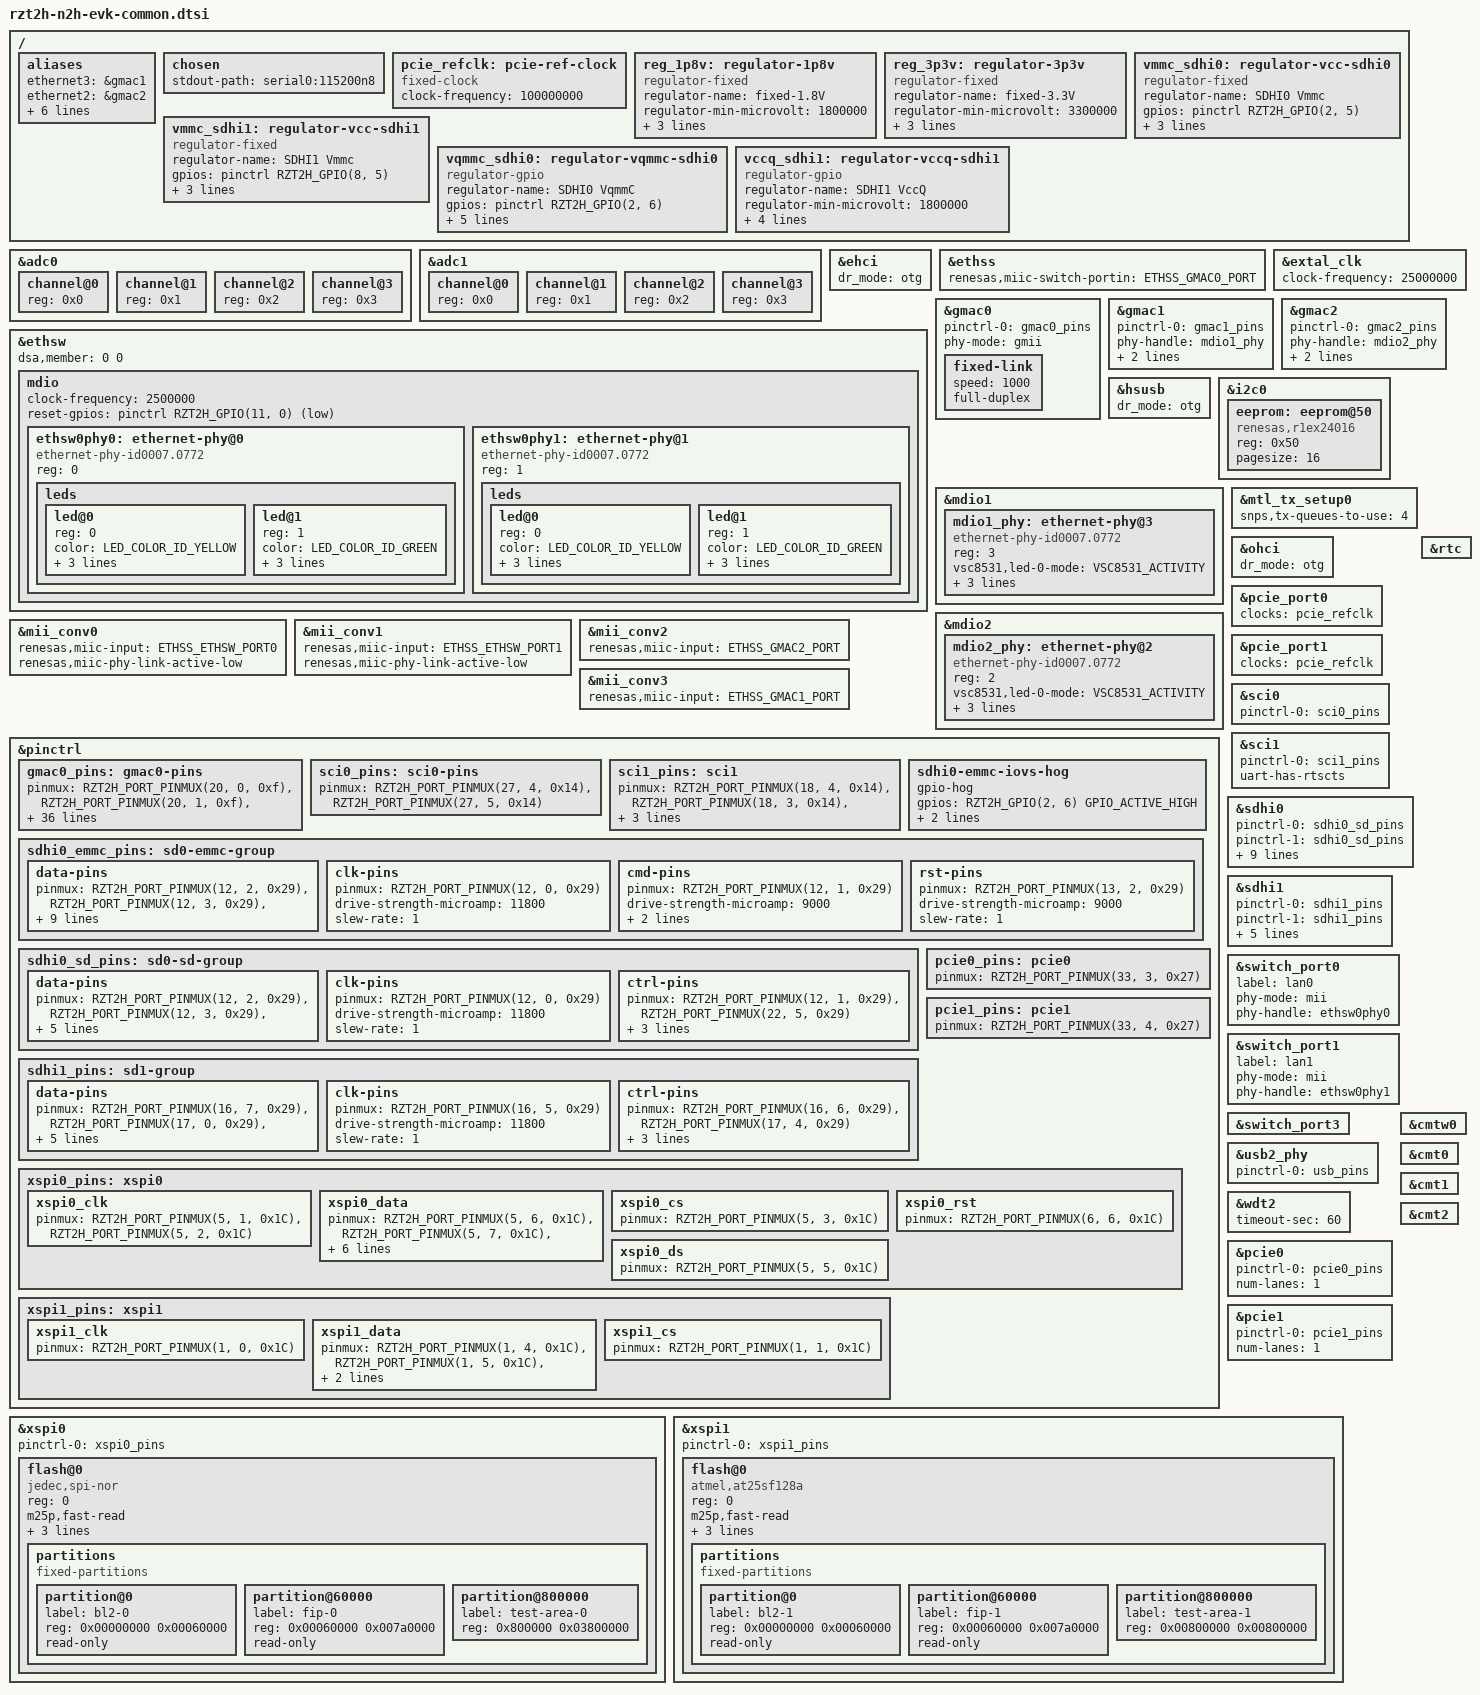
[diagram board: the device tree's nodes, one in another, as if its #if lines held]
// SPDX-License-Identifier: (GPL-2.0-only OR BSD-2-Clause)
/*
 * Common Device Tree Source for the RZ/T2H and RZ/N2H EVK boards.
 *
 * Copyright (C) 2025 Renesas Electronics Corp.
 */

#include <dt-bindings/gpio/gpio.h>
#include <dt-bindings/leds/common.h>
#include <dt-bindings/net/mscc-phy-vsc8531.h>
#include <dt-bindings/net/renesas,r9a09g077-pcs-miic.h>
#include <dt-bindings/pinctrl/renesas,r9a09g077-pinctrl.h>

/ {
	aliases {
		ethernet3 = &gmac1;
		ethernet2 = &gmac2;
		i2c0 = &i2c0;
		i2c1 = &i2c1;
		mmc0 = &sdhi0;
		mmc1 = &sdhi1;
		serial0 = &sci0;
		serial1 = &sci1;
	};

	chosen {
		stdout-path = "serial0:115200n8";
	};

	pcie_refclk: pcie-ref-clock {
		compatible = "fixed-clock";
		#clock-cells = <0>;
		clock-frequency = <100000000>;
	};

	reg_1p8v: regulator-1p8v {
		compatible = "regulator-fixed";
		regulator-name = "fixed-1.8V";
		regulator-min-microvolt = <1800000>;
		regulator-max-microvolt = <1800000>;
		regulator-boot-on;
		regulator-always-on;
	};

	reg_3p3v: regulator-3p3v {
		compatible = "regulator-fixed";
		regulator-name = "fixed-3.3V";
		regulator-min-microvolt = <3300000>;
		regulator-max-microvolt = <3300000>;
		regulator-boot-on;
		regulator-always-on;
	};

	vmmc_sdhi0: regulator-vcc-sdhi0 {
		compatible = "regulator-fixed";
		regulator-name = "SDHI0 Vmmc";
#if SD0_SD
		gpios = <&pinctrl RZT2H_GPIO(2, 5) GPIO_ACTIVE_HIGH>;
		enable-active-high;
#endif
		regulator-min-microvolt = <3300000>;
		regulator-max-microvolt = <3300000>;
	};

	vmmc_sdhi1: regulator-vcc-sdhi1 {
		compatible = "regulator-fixed";
		regulator-name = "SDHI1 Vmmc";
		gpios = <&pinctrl RZT2H_GPIO(8, 5) GPIO_ACTIVE_HIGH>;
		enable-active-high;
		regulator-min-microvolt = <3300000>;
		regulator-max-microvolt = <3300000>;
	};

#if SD0_SD
	vqmmc_sdhi0: regulator-vqmmc-sdhi0 {
		compatible = "regulator-gpio";
		regulator-name = "SDHI0 VqmmC";
		gpios = <&pinctrl RZT2H_GPIO(2, 6) GPIO_ACTIVE_HIGH>;
		regulator-min-microvolt = <1800000>;
		regulator-max-microvolt = <3300000>;
		gpios-states = <0>;
		states = <3300000 0>, <1800000 1>;
		regulator-ramp-delay = <60>;
	};
#endif

#if SD1_MICRO_SD
	vccq_sdhi1: regulator-vccq-sdhi1 {
		compatible = "regulator-gpio";
		regulator-name = "SDHI1 VccQ";
		regulator-min-microvolt = <1800000>;
		regulator-max-microvolt = <3300000>;
		gpios = <&pinctrl RZT2H_GPIO(8, 6) GPIO_ACTIVE_HIGH>;
		gpios-states = <0>;
		states = <3300000 0>, <1800000 1>;
	};
#endif
};

/*
 * ADC0 AN000 can be connected to a potentiometer on the board or
 * exposed on ADC header.
 *
 * T2H:
 * SW17[1] = ON, SW17[2] = OFF - Potentiometer
 * SW17[1] = OFF, SW17[2] = ON  - CN41 header
 * N2H:
 * DSW6[1] = OFF, DSW6[2] = ON - Potentiometer
 * DSW6[1] = ON, DSW6[2] = OFF - CN3 header
 */
&adc0 {
	status = "okay";

	channel@0 {
		reg = <0x0>;
	};

	channel@1 {
		reg = <0x1>;
	};

	channel@2 {
		reg = <0x2>;
	};

	channel@3 {
		reg = <0x3>;
	};
};

/*
 * ADC1 AN100 can be exposed on ADC header or on mikroBUS connector.
 *
 * T2H:
 * SW18[1] = ON, SW18[2] = OFF - CN42 header
 * SW18[1] = OFF, SW18[2] = ON - mikroBUS
 * N2H:
 * DSW6[3] = ON, DSW6[4] = OFF - CN4 header
 * DSW6[3] = OFF, DSW6[4] = ON - mikroBUS
 *
 * ADC1 AN101 can be exposed on ADC header or on Grove2 connector.
 *
 * T2H:
 * SW18[3] = ON, SW18[4] = OFF - CN42 header
 * SW18[3] = OFF, SW18[4] = ON - Grove2
 * N2H:
 * DSW6[5] = ON, DSW6[6] = OFF - CN4 header
 * DSW6[5] = OFF, DSW6[6] = ON - Grove2
 *
 * ADC1 AN102 can be exposed on ADC header or on Grove2 connector.
 *
 * T2H:
 * SW18[5] = ON, SW18[6] = OFF - CN42 header
 * SW18[5] = OFF, SW18[6] = ON - Grove2
 * N2H:
 * DSW6[7] = ON, DSW6[8] = OFF - CN4 header
 * DSW6[7] = OFF, DSW6[8] = ON - Grove2
 */
&adc1 {
	status = "okay";

	channel@0 {
		reg = <0x0>;
	};

	channel@1 {
		reg = <0x1>;
	};

	channel@2 {
		reg = <0x2>;
	};

	channel@3 {
		reg = <0x3>;
	};
};

&ehci {
	dr_mode = "otg";
	status = "okay";
};

&ethss {
	status = "okay";

	renesas,miic-switch-portin = <ETHSS_GMAC0_PORT>;
};

&ethsw {
	status = "okay";
	dsa,member = <0 0>;

	mdio {
		clock-frequency = <2500000>;
		#address-cells = <1>;
		#size-cells = <0>;
		/*
		 * P11_0 is connected to both the PHY0 and PHY1 reset pins.
		 *
		 * RZ/T2H EVK:
		 * SW6[2]: OFF, SW6[3]: ON, SW6[4]: OFF, SW6[5]: ON
		 *
		 * RZ/N2H EVK:
		 * DS12[3]: OFF, DS12[4]: ON
		 */
		reset-gpios = <&pinctrl RZT2H_GPIO(11, 0) GPIO_ACTIVE_LOW>;

		ethsw0phy0: ethernet-phy@0 {
			compatible = "ethernet-phy-id0007.0772", "ethernet-phy-ieee802.3-c22";
			reg = <0>;
			leds {
				#address-cells = <1>;
				#size-cells = <0>;

				led@0 {
					reg = <0>;
					color = <LED_COLOR_ID_YELLOW>;
					function = LED_FUNCTION_LAN;
					function-enumerator = <0>;
					default-state = "keep";
				};

				led@1 {
					reg = <1>;
					color = <LED_COLOR_ID_GREEN>;
					function = LED_FUNCTION_LAN;
					function-enumerator = <1>;
					default-state = "keep";
				};
			};
		};

		ethsw0phy1: ethernet-phy@1 {
			compatible = "ethernet-phy-id0007.0772", "ethernet-phy-ieee802.3-c22";
			reg = <1>;
			leds {
				#address-cells = <1>;
				#size-cells = <0>;

				led@0 {
					reg = <0>;
					color = <LED_COLOR_ID_YELLOW>;
					function = LED_FUNCTION_LAN;
					function-enumerator = <0>;
					default-state = "keep";
				};

				led@1 {
					reg = <1>;
					color = <LED_COLOR_ID_GREEN>;
					function = LED_FUNCTION_LAN;
					function-enumerator = <1>;
					default-state = "keep";
				};
			};
		};
	};
};

&extal_clk {
	clock-frequency = <25000000>;
};

&gmac0 {
	pinctrl-0 = <&gmac0_pins>;
	pinctrl-names = "default";
	status = "okay";
	phy-mode = "gmii";

	fixed-link {
		speed = <1000>;
		full-duplex;
	};
};

#if (SEL_GMAC1_OTHERS)
&gmac1 {
	pinctrl-0 = <&gmac1_pins>;
	pinctrl-names = "default";
	phy-handle = <&mdio1_phy>;
	phy-mode = "rgmii-id";
	pcs-handle = <&mii_conv3>;
	status = "okay";
};
#endif

&gmac2 {
	pinctrl-0 = <&gmac2_pins>;
	pinctrl-names = "default";
	phy-handle = <&mdio2_phy>;
	phy-mode = "rgmii-id";
	pcs-handle = <&mii_conv2>;
	status = "okay";
};

&hsusb {
	dr_mode = "otg";
	status = "okay";
};

&i2c0 {
	eeprom: eeprom@50 {
		compatible = "renesas,r1ex24016", "atmel,24c16";
		reg = <0x50>;
		pagesize = <16>;
	};
};

&mdio1 {
	mdio1_phy: ethernet-phy@3 {
		compatible = "ethernet-phy-id0007.0772", "ethernet-phy-ieee802.3-c22";
		reg = <3>;
		vsc8531,led-0-mode = <VSC8531_ACTIVITY>;
		vsc8531,led-1-mode = <VSC8531_LINK_ACTIVITY>;
		reset-assert-us = <2000>;
		reset-deassert-us = <15000>;
	};
};

&mdio2 {
	mdio2_phy: ethernet-phy@2 {
		compatible = "ethernet-phy-id0007.0772", "ethernet-phy-ieee802.3-c22";
		reg = <2>;
		vsc8531,led-0-mode = <VSC8531_ACTIVITY>;
		vsc8531,led-1-mode = <VSC8531_LINK_ACTIVITY>;
		reset-assert-us = <2000>;
		reset-deassert-us = <15000>;
	};
};

&mii_conv0 {
	renesas,miic-input = <ETHSS_ETHSW_PORT0>;
	renesas,miic-phy-link-active-low;
	status = "okay";
};

&mii_conv1 {
	renesas,miic-input = <ETHSS_ETHSW_PORT1>;
	renesas,miic-phy-link-active-low;
	status = "okay";
};

&mii_conv2 {
	renesas,miic-input = <ETHSS_GMAC2_PORT>;
	status = "okay";
};

&mii_conv3 {
	renesas,miic-input = <ETHSS_GMAC1_PORT>;
	status = "okay";
};

/*
 * The Tx fifo depth is 8192 and we have 8 Tx queues available, so in
 * total we have 1024 bytes per queue. When using as a CPU port in a DSA
 * configuration, MTU is configured to 1500 bytes which is larger than the
 * per-queue fifo size. Reduce the number of Tx queues to 4 to have
 * 2048 bytes per queue to accommodate the MTU.
 */
&mtl_tx_setup0 {
	snps,tx-queues-to-use = <4>;
};

&ohci {
	dr_mode = "otg";
	status = "okay";
};

&pcie_port0 {
	clocks = <&pcie_refclk>;
	clock-names = "ref";
};

&pcie_port1 {
	clocks = <&pcie_refclk>;
	clock-names = "ref";
};

&pinctrl {
	/*
	 * GMAC0 Pin Configuration:
	 * ------------------------
	 *
	 * RZ/T2H EVK:
	 * Signal     | Pin     | SW4 Settings
	 * -----------|---------|-------------------------
	 * ETH1_CRS   | P27_0   | SW4[1]: ON, SW4[2]: OFF
	 * ETH1_COL   | P27_1   | SW4[3]: ON, SW4[4]: OFF
	 *
	 * RZ/N2H EVK:
	 * Signal     | Pin     | DSW13 and DSW21 Settings
	 * -----------|---------|-------------------------
	 * ETH1_TXER  | P26_6   | DSW21[1]: ON, DSW21[2]: OFF, DSW21[3]: ON
	 * ETH1_RXER  | P26_7   | DSW13[1]: ON, DSW13[2]: OFF
	 * ETH1_CRS   | P27_0   | DSW13[3]: ON, DSW13[4]: OFF
	 * ETH1_COL   | P27_1   | DSW13[5]: ON, DSW13[6]: OFF
	 */
	gmac0_pins: gmac0-pins {
		pinmux = <RZT2H_PORT_PINMUX(20, 0, 0xf)>, /* ETH0_TXCLK */
			 <RZT2H_PORT_PINMUX(20, 1, 0xf)>, /* ETH0_TXD0 */
			 <RZT2H_PORT_PINMUX(20, 2, 0xf)>, /* ETH0_TXD1 */
			 <RZT2H_PORT_PINMUX(20, 3, 0xf)>, /* ETH0_TXD2 */
			 <RZT2H_PORT_PINMUX(20, 4, 0xf)>, /* ETH0_TXD3 */
			 <RZT2H_PORT_PINMUX(20, 5, 0xf)>, /* ETH0_TXEN */
			 <RZT2H_PORT_PINMUX(20, 6, 0xf)>, /* ETH0_RXCLK */
			 <RZT2H_PORT_PINMUX(20, 7, 0xf)>, /* ETH0_RXD0 */
			 <RZT2H_PORT_PINMUX(21, 0, 0xf)>, /* ETH0_RXD1 */
			 <RZT2H_PORT_PINMUX(21, 1, 0xf)>, /* ETH0_RXD2 */
			 <RZT2H_PORT_PINMUX(21, 2, 0xf)>, /* ETH0_RXD3 */
			 <RZT2H_PORT_PINMUX(21, 3, 0xf)>, /* ETH0_RXDV */
			 <RZT2H_PORT_PINMUX(22, 1, 0xf)>, /* ETH0_TXER */
			 <RZT2H_PORT_PINMUX(22, 2, 0xf)>, /* ETH0_RXER */
			 <RZT2H_PORT_PINMUX(22, 3, 0xf)>, /* ETH0_CRS */
			 <RZT2H_PORT_PINMUX(22, 4, 0xf)>, /* ETH0_COL */
			 <RZT2H_PORT_PINMUX(21, 7, 0x2)>, /* ETH0_REFCLK */
			 <RZT2H_PORT_PINMUX(24, 5, 0xf)>, /* ETH1_TXCLK */
			 <RZT2H_PORT_PINMUX(24, 6, 0xf)>, /* ETH1_TXD0 */
			 <RZT2H_PORT_PINMUX(24, 7, 0xf)>, /* ETH1_TXD1 */
			 <RZT2H_PORT_PINMUX(25, 0, 0xf)>, /* ETH1_TXD2 */
			 <RZT2H_PORT_PINMUX(25, 1, 0xf)>, /* ETH1_TXD3 */
			 <RZT2H_PORT_PINMUX(25, 2, 0xf)>, /* ETH1_TXEN */
			 <RZT2H_PORT_PINMUX(25, 3, 0xf)>, /* ETH1_RXCLK */
			 <RZT2H_PORT_PINMUX(25, 4, 0xf)>, /* ETH1_RXDD0 */
			 <RZT2H_PORT_PINMUX(25, 5, 0xf)>, /* ETH1_RXDD1 */
			 <RZT2H_PORT_PINMUX(25, 6, 0xf)>, /* ETH1_RXDD2 */
			 <RZT2H_PORT_PINMUX(25, 7, 0xf)>, /* ETH1_RXD3 */
			 <RZT2H_PORT_PINMUX(26, 0, 0xf)>, /* ETH1_RXDV */
			 <RZT2H_PORT_PINMUX(26, 6, 0xf)>, /* ETH1_TXER */
			 <RZT2H_PORT_PINMUX(26, 7, 0xf)>, /* ETH1_RXER */
			 <RZT2H_PORT_PINMUX(27, 0, 0xf)>, /* ETH1_CRS */
			 <RZT2H_PORT_PINMUX(27, 1, 0xf)>, /* ETH1_COL */
			 <RZT2H_PORT_PINMUX(26, 4, 0x2)>, /* ETH1_REFCLK */
			 <RZT2H_PORT_PINMUX(21, 4, 0x11)>, /* ETHSW_MDC */
			 <RZT2H_PORT_PINMUX(21, 5, 0x11)>, /* ETHSW_MDIO */
			 <RZT2H_PORT_PINMUX(21, 6, 0x11)>, /* ETHSW_PHYLINK0 */
			 <RZT2H_PORT_PINMUX(26, 3, 0x11)>; /* ETHSW_PHYLINK1 */
	};

	/*
	 * SCI0 Pin Configuration:
	 * ------------------------
	 * Signal     | Pin     | RZ/T2H (SW4) | RZ/N2H (DSW9)
	 * -----------|---------|--------------|---------------
	 * SCI0_RXD   | P27_4   | 5: ON, 6: OFF| 1: ON, 2: OFF
	 * SCI0_TXD   | P27_5   | 7: ON, 8: OFF| 3: ON, 4: OFF
	 */
	sci0_pins: sci0-pins {
		pinmux = <RZT2H_PORT_PINMUX(27, 4, 0x14)>,
			 <RZT2H_PORT_PINMUX(27, 5, 0x14)>;
	};

	sci1_pins: sci1 {
		pinmux = <RZT2H_PORT_PINMUX(18, 4, 0x14)>, /* SCI1_TXD */
			 <RZT2H_PORT_PINMUX(18, 3, 0x14)>, /* SCI1_RXD */
			 <RZT2H_PORT_PINMUX(18, 6, 0x14)>, /* CTS1# */
			 <RZT2H_PORT_PINMUX(18, 5, 0x14)>; /* RTS1# */
		bias-pull-up;
	};

#if SD0_EMMC
	sdhi0-emmc-iovs-hog {
		gpio-hog;
		gpios = <RZT2H_GPIO(2, 6) GPIO_ACTIVE_HIGH>;
		output-high;
		line-name = "SD0_IOVS";
	};
#endif

	sdhi0_emmc_pins: sd0-emmc-group {
		data-pins {
			pinmux = <RZT2H_PORT_PINMUX(12, 2, 0x29)>, /* SD0_DATA0 */
				 <RZT2H_PORT_PINMUX(12, 3, 0x29)>, /* SD0_DATA1 */
				 <RZT2H_PORT_PINMUX(12, 4, 0x29)>, /* SD0_DATA2 */
				 <RZT2H_PORT_PINMUX(12, 5, 0x29)>, /* SD0_DATA3 */
				 <RZT2H_PORT_PINMUX(12, 6, 0x29)>, /* SD0_DATA4 */
				 <RZT2H_PORT_PINMUX(12, 7, 0x29)>, /* SD0_DATA5 */
				 <RZT2H_PORT_PINMUX(13, 0, 0x29)>, /* SD0_DATA6 */
				 <RZT2H_PORT_PINMUX(13, 1, 0x29)>; /* SD0_DATA7 */
			drive-strength-microamp = <9000>;
			slew-rate = <1>;
			input-schmitt-disable;
		};

		clk-pins {
			pinmux = <RZT2H_PORT_PINMUX(12, 0, 0x29)>; /* SD0_CLK */
			drive-strength-microamp = <11800>;
			slew-rate = <1>;
		};

		cmd-pins {
			pinmux = <RZT2H_PORT_PINMUX(12, 1, 0x29)>; /* SD0_CMD */
			drive-strength-microamp = <9000>;
			slew-rate = <1>;
			input-schmitt-disable;
		};

		rst-pins {
			pinmux = <RZT2H_PORT_PINMUX(13, 2, 0x29)>; /* SD0_RST# */
			drive-strength-microamp = <9000>;
			slew-rate = <1>;
		};
	};

	sdhi0_sd_pins: sd0-sd-group {
		data-pins {
			pinmux = <RZT2H_PORT_PINMUX(12, 2, 0x29)>, /* SD0_DATA0 */
				 <RZT2H_PORT_PINMUX(12, 3, 0x29)>, /* SD0_DATA1 */
				 <RZT2H_PORT_PINMUX(12, 4, 0x29)>, /* SD0_DATA2 */
				 <RZT2H_PORT_PINMUX(12, 5, 0x29)>; /* SD0_DATA3 */
			drive-strength-microamp = <9000>;
			slew-rate = <1>;
			input-schmitt-disable;
		};

		clk-pins {
			pinmux = <RZT2H_PORT_PINMUX(12, 0, 0x29)>; /* SD0_CLK */
			drive-strength-microamp = <11800>;
			slew-rate = <1>;
		};

		ctrl-pins {
			pinmux = <RZT2H_PORT_PINMUX(12, 1, 0x29)>, /* SD0_CMD */
				 <RZT2H_PORT_PINMUX(22, 5, 0x29)>; /* SD0_CD */
			drive-strength-microamp = <9000>;
			slew-rate = <1>;
			input-schmitt-disable;
		};
	};

	sdhi1_pins: sd1-group {
		data-pins {
			pinmux = <RZT2H_PORT_PINMUX(16, 7, 0x29)>, /* SD1_DATA0 */
				 <RZT2H_PORT_PINMUX(17, 0, 0x29)>, /* SD1_DATA1 */
				 <RZT2H_PORT_PINMUX(17, 1, 0x29)>, /* SD1_DATA2 */
				 <RZT2H_PORT_PINMUX(17, 2, 0x29)>; /* SD1_DATA3 */
			drive-strength-microamp = <9000>;
			slew-rate = <1>;
			input-schmitt-disable;
		};

		clk-pins {
			pinmux = <RZT2H_PORT_PINMUX(16, 5, 0x29)>; /* SD1_CLK */
			drive-strength-microamp = <11800>;
			slew-rate = <1>;
		};

		ctrl-pins {
			pinmux = <RZT2H_PORT_PINMUX(16, 6, 0x29)>, /* SD1_CMD */
				 <RZT2H_PORT_PINMUX(17, 4, 0x29)>; /* SD1_CD */
			drive-strength-microamp = <9000>;
			slew-rate = <1>;
			input-schmitt-disable;
		};
	};

#if (!SEL_GMAC1_OTHERS)
#if (PCIE_SEL == PCIE0 || PCIE_SEL == PCIE0_PCIE1)
	pcie0_pins: pcie0 {
		pinmux = <RZT2H_PORT_PINMUX(33, 3, 0x27)>; /* PCIE_RST_OUT0B */
	};
#endif

#if (PCIE_SEL == PCIE1 || PCIE_SEL == PCIE0_PCIE1)
	pcie1_pins: pcie1 {
		pinmux = <RZT2H_PORT_PINMUX(33, 4, 0x27)>; /* PCIE_RST_OUT1B */
	};
#endif
#endif

	xspi0_pins: xspi0 {
		xspi0_clk {
			pinmux = <RZT2H_PORT_PINMUX(5, 1, 0x1C)>, /* XSPI0_CKP */
				 <RZT2H_PORT_PINMUX(5, 2, 0x1C)>; /* XSPI0_CKN */
		};

		xspi0_data {
			pinmux = <RZT2H_PORT_PINMUX(5, 6, 0x1C)>, /* XSPI0_IO0 */
				 <RZT2H_PORT_PINMUX(5, 7, 0x1C)>, /* XSPI0_IO1 */
				 <RZT2H_PORT_PINMUX(6, 0, 0x1C)>, /* XSPI0_IO2 */
				 <RZT2H_PORT_PINMUX(6, 1, 0x1C)>, /* XSPI0_IO3 */
				 <RZT2H_PORT_PINMUX(6, 2, 0x1C)>, /* XSPI0_IO4 */
				 <RZT2H_PORT_PINMUX(6, 3, 0x1C)>, /* XSPI0_IO5 */
				 <RZT2H_PORT_PINMUX(6, 4, 0x1C)>, /* XSPI0_IO6 */
				 <RZT2H_PORT_PINMUX(6, 5, 0x1C)>; /* XSPI0_IO7 */
		};

		xspi0_cs {
			pinmux = <RZT2H_PORT_PINMUX(5, 3, 0x1C)>; /* XSPI0_CS0 */
		};

		xspi0_rst {
			pinmux = <RZT2H_PORT_PINMUX(6, 6, 0x1C)>; /* XSPI0_RESET0 */
		};

		xspi0_ds {
			pinmux = <RZT2H_PORT_PINMUX(5, 5, 0x1C)>; /* XSPI0_DS */
		};
	};

	xspi1_pins: xspi1 {
		xspi1_clk {
			pinmux = <RZT2H_PORT_PINMUX(1, 0, 0x1C)>; /* XSPI1_CKP */
		};

		xspi1_data {
			pinmux = <RZT2H_PORT_PINMUX(1, 4, 0x1C)>, /* XSPI1_IO0 */
				 <RZT2H_PORT_PINMUX(1, 5, 0x1C)>, /* XSPI1_IO1 */
				 <RZT2H_PORT_PINMUX(1, 6, 0x1C)>, /* XSPI1_IO2 */
				 <RZT2H_PORT_PINMUX(1, 7, 0x1C)>; /* XSPI1_IO3 */
		};

		xspi1_cs {
			pinmux = <RZT2H_PORT_PINMUX(1, 1, 0x1C)>; /* XSPI1_CS0 */
		};
	};
};

&sci0 {
	pinctrl-0 = <&sci0_pins>;
	pinctrl-names = "default";
	status = "okay";
};

&sci1 {
	pinctrl-0 = <&sci1_pins>;
	pinctrl-names = "default";

	uart-has-rtscts;
	status = "okay";
};

#if SD0_EMMC
&sdhi0 {
	pinctrl-0 = <&sdhi0_emmc_pins>;
	pinctrl-1 = <&sdhi0_emmc_pins>;
	pinctrl-names = "default", "state_uhs";
	vmmc-supply = <&vmmc_sdhi0>;
	vqmmc-supply = <&reg_1p8v>;
	bus-width = <8>;
	non-removable;
	mmc-hs200-1_8v;
	fixed-emmc-driver-type = <1>;
	status = "okay";
};
#endif

#if SD0_SD
&sdhi0 {
	pinctrl-0 = <&sdhi0_sd_pins>;
	pinctrl-1 = <&sdhi0_sd_pins>;
	pinctrl-names = "default", "state_uhs";
	vmmc-supply = <&vmmc_sdhi0>;
	vqmmc-supply = <&vqmmc_sdhi0>;
	wp-gpios = <&pinctrl RZT2H_GPIO(22, 6) GPIO_ACTIVE_HIGH>;
	bus-width = <4>;
	sd-uhs-sdr50;
	sd-uhs-sdr104;
	status = "okay";
};
#endif

#if SD1_MICRO_SD
&sdhi1 {
	pinctrl-0 = <&sdhi1_pins>;
	pinctrl-1 = <&sdhi1_pins>;
	pinctrl-names = "default", "state_uhs";
	vmmc-supply = <&vmmc_sdhi1>;
	vqmmc-supply = <&vccq_sdhi1>;
	bus-width = <4>;
	sd-uhs-sdr50;
	sd-uhs-sdr104;
	status = "okay";
};
#endif

&switch_port0 {
	label = "lan0";
	phy-mode = "mii";
	phy-handle = <&ethsw0phy0>;
	status = "okay";
};

&switch_port1 {
	label = "lan1";
	phy-mode = "mii";
	phy-handle = <&ethsw0phy1>;
	status = "okay";
};

&switch_port3 {
	status = "okay";
};

&usb2_phy {
	pinctrl-0 = <&usb_pins>;
	pinctrl-names = "default";

	status = "okay";
};

&wdt2 {
	status = "okay";
	timeout-sec = <60>;
};

&rtc {
	status = "okay";
};

#if (!SEL_GMAC1_OTHERS)
#if (PCIE_SEL == PCIE0 || PCIE_SEL == PCIE0_PCIE1)
&pcie0 {
	pinctrl-0 = <&pcie0_pins>;
	pinctrl-names = "default";
#if (PCIE_SEL == PCIE0_PCIE1)
	num-lanes = <1>;
#else
	num-lanes = <2>;
#endif
	status = "okay";
};
#endif

#if (PCIE_SEL == PCIE1 || PCIE_SEL == PCIE0_PCIE1)
&pcie1 {
	pinctrl-0 = <&pcie1_pins>;
	pinctrl-names = "default";
	num-lanes = <1>;
	status = "okay";
};
#endif
#endif

&xspi0 {
	pinctrl-0 = <&xspi0_pins>;
	pinctrl-names = "default";

	status = "okay";

	flash@0 {
		compatible = "jedec,spi-nor";
		reg = <0>;
		m25p,fast-read;
		spi-max-frequency = <50000000>;
		/*
		 * Configure for 1-bit mode to prevent the BootROM from failing
		 * to load the first-stage bootloader following a watchdog reset.
		 */
		spi-tx-bus-width = <1>;
		spi-rx-bus-width = <1>;

		partitions {
			compatible = "fixed-partitions";
			#address-cells = <1>;
			#size-cells = <1>;

			partition@0 {
				label = "bl2-0";
				reg = <0x00000000 0x00060000>;
				read-only;
			};

			partition@60000 {
				label = "fip-0";
				reg = <0x00060000 0x007a0000>;
				read-only;
			};

			partition@800000 {
				label = "test-area-0";
				reg = <0x800000 0x03800000>;
			};
		};
	};
};

&xspi1 {
	pinctrl-0 = <&xspi1_pins>;
	pinctrl-names = "default";

	status = "okay";

	flash@0 {
		compatible = "atmel,at25sf128a", "jedec,spi-nor";
		reg = <0>;
		m25p,fast-read;
		spi-max-frequency = <50000000>;
		spi-tx-bus-width = <1>;
		spi-rx-bus-width = <1>;

		partitions {
			compatible = "fixed-partitions";
			#address-cells = <1>;
			#size-cells = <1>;

			partition@0 {
				label = "bl2-1";
				reg = <0x00000000 0x00060000>;
				read-only;
			};

			partition@60000 {
				label = "fip-1";
				reg = <0x00060000 0x007a0000>;
				read-only;
			};

			partition@800000 {
				label = "test-area-1";
				reg = <0x00800000 0x00800000>;
			};
		};
	};
};

&cmtw0 {
	status = "okay";
};

&cmt0 {
	status = "okay";
};

&cmt1 {
	status = "okay";
};

&cmt2 {
	status = "okay";
};
